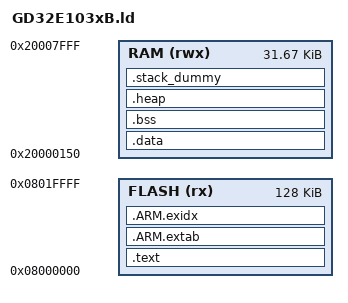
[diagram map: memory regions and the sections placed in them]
#if !defined(MBED_APP_START)
  #define MBED_APP_START 0x08000000
#endif

#if !defined(MBED_APP_SIZE)
  #define MBED_APP_SIZE 128K
#endif

#if !defined(MBED_BOOT_STACK_SIZE)
  #define MBED_BOOT_STACK_SIZE 0x400
#endif

/* specify memory regions */
MEMORY
{ 
  FLASH (rx) : ORIGIN = MBED_APP_START, LENGTH = MBED_APP_SIZE
  RAM (rwx)  : ORIGIN = 0x20000150, LENGTH = 32K - 0x150
}

/* define output sections */ 
ENTRY(Reset_Handler)

SECTIONS
{
    .text :
    {
        KEEP(*(.isr_vector))
        *(.text*)
        KEEP(*(.init))
        KEEP(*(.fini))

        /* .ctors */
        *crtbegin.o(.ctors)
        *crtbegin?.o(.ctors)
        *(EXCLUDE_FILE(*crtend?.o *crtend.o) .ctors)
        *(SORT(.ctors.*))
        *(.ctors)

        /* .dtors */
        *crtbegin.o(.dtors)
        *crtbegin?.o(.dtors)
        *(EXCLUDE_FILE(*crtend?.o *crtend.o) .dtors)
        *(SORT(.dtors.*))
        *(.dtors)

        *(.rodata*)

        KEEP(*(.eh_frame*))
    } > FLASH

    .ARM.extab : 
    {
        *(.ARM.extab* .gnu.linkonce.armextab.*)
    } > FLASH

    __exidx_start = .;
    .ARM.exidx :
    {
        *(.ARM.exidx* .gnu.linkonce.armexidx.*)
    } > FLASH
    __exidx_end = .;

    __etext = .;
    _sidata = .;

    .data : AT (__etext)
    {
        __data_start__ = .;
        _sdata = .;
        *(vtable)
        *(.data*)

        . = ALIGN(8);
        /* preinit data */
        PROVIDE_HIDDEN (__preinit_array_start = .);
        KEEP(*(.preinit_array))
        PROVIDE_HIDDEN (__preinit_array_end = .);

        . = ALIGN(8);
        /* init data */
        PROVIDE_HIDDEN (__init_array_start = .);
        KEEP(*(SORT(.init_array.*)))
        KEEP(*(.init_array))
        PROVIDE_HIDDEN (__init_array_end = .);


        . = ALIGN(8);
        /* finit data */
        PROVIDE_HIDDEN (__fini_array_start = .);
        KEEP(*(SORT(.fini_array.*)))
        KEEP(*(.fini_array))
        PROVIDE_HIDDEN (__fini_array_end = .);

        KEEP(*(.jcr*))
        . = ALIGN(8);
        /* All data end */
        __data_end__ = .;
        _edata = .;

    } > RAM

    .bss :
    {
        . = ALIGN(8);
        __bss_start__ = .;
        _sbss = .;
        *(.bss*)
        *(COMMON)
        . = ALIGN(8);
        __bss_end__ = .;
        _ebss = .;
    } > RAM
    
    .heap (COPY):
    {
        __end__ = .;
        end = __end__;
        *(.heap*)
        . = ORIGIN(RAM) + LENGTH(RAM) - MBED_BOOT_STACK_SIZE;
        __HeapLimit = .;
    } > RAM

    .stack_dummy (COPY):
    {
        *(.stack*)
    } > RAM

    /* initializes stack on the end of block */
    __StackTop = ORIGIN(RAM) + LENGTH(RAM);
    _estack = __StackTop;
    __StackLimit = __StackTop - MBED_BOOT_STACK_SIZE;
    PROVIDE(__stack = __StackTop);
    
    ASSERT(__StackLimit >= __HeapLimit, "region RAM overflowed with stack")
}

